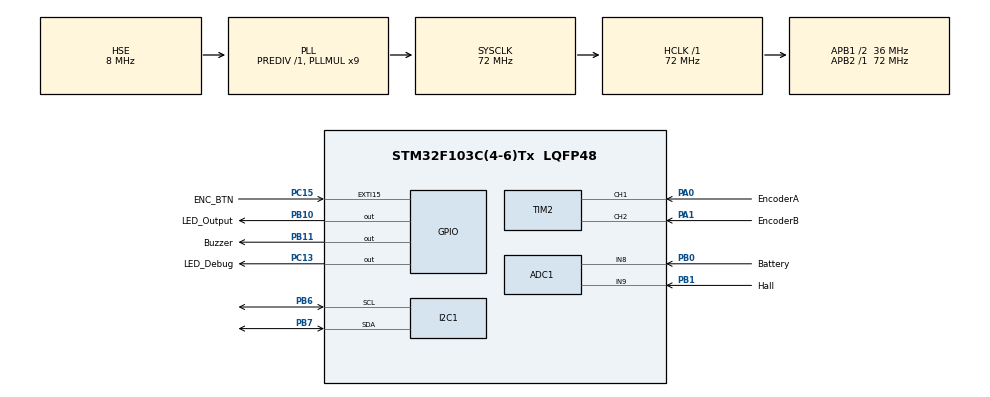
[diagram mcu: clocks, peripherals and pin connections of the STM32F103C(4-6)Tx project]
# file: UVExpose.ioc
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ADC1.Channel-0\#ChannelRegularConversion=ADC_CHANNEL_9
ADC1.NbrOfConversionFlag=1
ADC1.Rank-0\#ChannelRegularConversion=1
ADC1.SamplingTime-0\#ChannelRegularConversion=ADC_SAMPLETIME_1CYCLE_5
ADC1.master=1
I2C1.I2C_Mode=I2C_Fast
Mcu.Family=STM32F1
Mcu.Name=STM32F103C(4-6)Tx
Mcu.Package=LQFP48
NVIC.EXTI15_10_IRQn=true\:0\:0\:false\:false\:true\:true\:true\:true
NVIC.PriorityGroup=NVIC_PRIORITYGROUP_4
PA0-WKUP.GPIO_Label=EncoderA
PA0-WKUP.GPIO_PuPd=GPIO_PULLUP
PA0-WKUP.Signal=S_TIM2_CH1_ETR
PA1.GPIO_Label=EncoderB
PA1.GPIO_PuPd=GPIO_PULLUP
PA1.Signal=S_TIM2_CH2
PA13.Mode=Serial_Wire
PA13.Signal=SYS_JTMS-SWDIO
PA14.Mode=Serial_Wire
PA14.Signal=SYS_JTCK-SWCLK
PB0.GPIO_Label=Battery
PB0.Signal=ADCx_IN8
PB1.GPIO_Label=Hall
PB1.Signal=ADCx_IN9
PB10.GPIO_Label=LED_Output
PB10.GPIO_PuPd=GPIO_PULLDOWN
PB10.Signal=GPIO_Output
PB11.GPIO_Label=Buzzer
PB11.Signal=GPIO_Output
PB6.Mode=I2C
PB6.Signal=I2C1_SCL
PB7.Mode=I2C
PB7.Signal=I2C1_SDA
PC13-TAMPER-RTC.GPIO_Label=LED_Debug
PC13-TAMPER-RTC.Signal=GPIO_Output
PC15-OSC32_OUT.GPIO_Label=ENC_BTN
PC15-OSC32_OUT.GPIO_ModeDefaultEXTI=GPIO_MODE_IT_RISING_FALLING
PC15-OSC32_OUT.GPIO_PuPd=GPIO_NOPULL
PC15-OSC32_OUT.Signal=GPXTI15
PD0-OSC_IN.Mode=HSE-External-Oscillator
PD0-OSC_IN.Signal=RCC_OSC_IN
PD1-OSC_OUT.Mode=HSE-External-Oscillator
PD1-OSC_OUT.Signal=RCC_OSC_OUT
ProjectManager.HeapSize=0x200
ProjectManager.StackSize=0x400
ProjectManager.TargetToolchain=STM32CubeIDE
RCC.ADCPresc=RCC_ADCPCLK2_DIV6
RCC.AHBFreq_Value=72000000
RCC.APB1CLKDivider=RCC_HCLK_DIV2
RCC.APB1Freq_Value=36000000
RCC.APB1TimFreq_Value=72000000
RCC.APB2Freq_Value=72000000
RCC.APB2TimFreq_Value=72000000
RCC.HCLKFreq_Value=72000000
RCC.PLLMUL=RCC_PLL_MUL9
RCC.PLLSourceVirtual=RCC_PLLSOURCE_HSE
RCC.SYSCLKFreq_VALUE=72000000
RCC.SYSCLKSource=RCC_SYSCLKSOURCE_PLLCLK
RCC.USBFreq_Value=72000000
SH.ADCx_IN8.0=ADC1_IN8,IN8
SH.ADCx_IN9.0=ADC1_IN9,IN9
SH.S_TIM2_CH1_ETR.0=TIM2_CH1,Encoder_Interface
SH.S_TIM2_CH2.0=TIM2_CH2,Encoder_Interface
TIM2.EncoderMode=TIM_ENCODERMODE_TI12
TIM2.IC1Filter=15
TIM2.IC2Filter=15
board=custom

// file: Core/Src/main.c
/* USER CODE BEGIN Header */
/**
  ******************************************************************************
  * @file           : main.c
  * @brief          : Main program body
  ******************************************************************************
  * @attention
  *
  * Copyright (c) 2026 STMicroelectronics.
  * All rights reserved.
  *
  * This software is licensed under terms that can be found in the LICENSE file
  * in the root directory of this software component.
  * If no LICENSE file comes with this software, it is provided AS-IS.
  *
  ******************************************************************************
  */
/* USER CODE END Header */
#include "main.h"
#include "adc.h"
#include "i2c.h"
#include "tim.h"
#include "gpio.h"

/* USER CODE BEGIN Includes */
#include "App/app_controller.h"
/* USER CODE END Includes */

void SystemClock_Config(void);

int main(void)
{

  /* MCU Configuration--------------------------------------------------------*/

  /* Reset of all peripherals, Initializes the Flash interface and the Systick. */
  HAL_Init();

  /* Configure the system clock */
  SystemClock_Config();

  /* Initialize all configured peripherals */
  MX_GPIO_Init();
  MX_I2C1_Init();
  MX_TIM2_Init();
  MX_ADC1_Init();
  /* USER CODE BEGIN 2 */
  App_Init(&hadc1);
  /* USER CODE END 2 */

  /* Infinite loop */
  /* USER CODE BEGIN WHILE */
  while (1)
  {
	  App_Process();
    /* USER CODE END WHILE */

  }
}

void SystemClock_Config(void)
{
  RCC_OscInitTypeDef RCC_OscInitStruct = {0};
  RCC_ClkInitTypeDef RCC_ClkInitStruct = {0};
  RCC_PeriphCLKInitTypeDef PeriphClkInit = {0};

  /** Initializes the RCC Oscillators according to the specified parameters
  * in the RCC_OscInitTypeDef structure.
  */
  RCC_OscInitStruct.OscillatorType = RCC_OSCILLATORTYPE_HSE;
  RCC_OscInitStruct.HSEState = RCC_HSE_ON;
  RCC_OscInitStruct.HSEPredivValue = RCC_HSE_PREDIV_DIV1;
  RCC_OscInitStruct.HSIState = RCC_HSI_ON;
  RCC_OscInitStruct.PLL.PLLState = RCC_PLL_ON;
  RCC_OscInitStruct.PLL.PLLSource = RCC_PLLSOURCE_HSE;
  RCC_OscInitStruct.PLL.PLLMUL = RCC_PLL_MUL9;
  if (HAL_RCC_OscConfig(&RCC_OscInitStruct) != HAL_OK)
  {
    Error_Handler();
  }

  /** Initializes the CPU, AHB and APB buses clocks
  */
  RCC_ClkInitStruct.ClockType = RCC_CLOCKTYPE_HCLK|RCC_CLOCKTYPE_SYSCLK
                              |RCC_CLOCKTYPE_PCLK1|RCC_CLOCKTYPE_PCLK2;
  RCC_ClkInitStruct.SYSCLKSource = RCC_SYSCLKSOURCE_PLLCLK;
  RCC_ClkInitStruct.AHBCLKDivider = RCC_SYSCLK_DIV1;
  RCC_ClkInitStruct.APB1CLKDivider = RCC_HCLK_DIV2;
  RCC_ClkInitStruct.APB2CLKDivider = RCC_HCLK_DIV1;

  if (HAL_RCC_ClockConfig(&RCC_ClkInitStruct, FLASH_LATENCY_2) != HAL_OK)
  {
    Error_Handler();
  }
  PeriphClkInit.PeriphClockSelection = RCC_PERIPHCLK_ADC;
  PeriphClkInit.AdcClockSelection = RCC_ADCPCLK2_DIV6;
  if (HAL_RCCEx_PeriphCLKConfig(&PeriphClkInit) != HAL_OK)
  {
    Error_Handler();
  }
}

void Error_Handler(void)
{
  __disable_irq();
  while (1)
  {
  }
}
